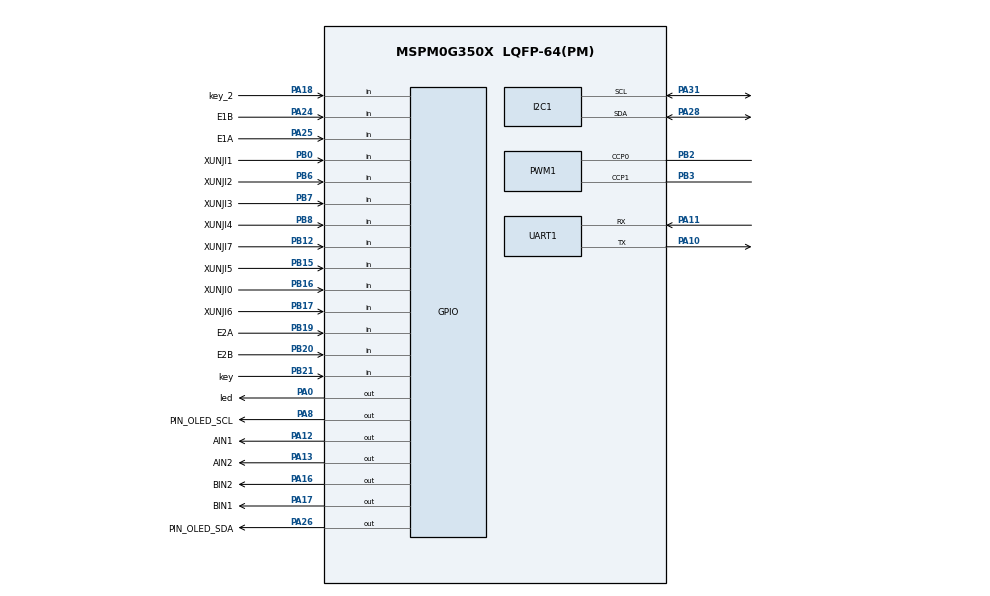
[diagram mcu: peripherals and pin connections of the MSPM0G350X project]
/**
 * @cliArgs --device "MSPM0G350X" --part "Default" --package "LQFP-64(PM)" --product "mspm0_sdk@2.10.00.04"
 * @versions {"tool":"1.27.0+4565"}
 */

/**
 * Import the modules used in this configuration.
 */
const ADC12   = scripting.addModule("/ti/driverlib/ADC12", {}, false);
const ADC121  = ADC12.addInstance();
const GPIO    = scripting.addModule("/ti/driverlib/GPIO", {}, false);
const GPIO1   = GPIO.addInstance();
const GPIO2   = GPIO.addInstance();
const GPIO3   = GPIO.addInstance();
const GPIO4   = GPIO.addInstance();
const GPIO5   = GPIO.addInstance();
const GPIO6   = GPIO.addInstance();
const GPIO7   = GPIO.addInstance();
const GPIO8   = GPIO.addInstance();
const I2C     = scripting.addModule("/ti/driverlib/I2C", {}, false);
const I2C1    = I2C.addInstance();
const PWM     = scripting.addModule("/ti/driverlib/PWM", {}, false);
const PWM1    = PWM.addInstance();
const SYSCTL  = scripting.addModule("/ti/driverlib/SYSCTL");
const SYSTICK = scripting.addModule("/ti/driverlib/SYSTICK");
const TIMER   = scripting.addModule("/ti/driverlib/TIMER", {}, false);
const TIMER1  = TIMER.addInstance();
const UART    = scripting.addModule("/ti/driverlib/UART", {}, false);
const UART1   = UART.addInstance();
const UART2   = UART.addInstance();

/**
 * Write custom configuration values to the imported modules.
 */
const divider7       = system.clockTree["PLL_PDIV"];
divider7.divideValue = 2;

const divider9       = system.clockTree["UDIV"];
divider9.divideValue = 2;

const gate7  = system.clockTree["MFCLKGATE"];
gate7.enable = true;

const multiplier2         = system.clockTree["PLL_QDIV"];
multiplier2.multiplyValue = 5;

const mux8       = system.clockTree["HSCLKMUX"];
mux8.inputSelect = "HSCLKMUX_SYSPLL2X";

ADC121.$name                      = "ADC12_0";
ADC121.resolution                 = "DL_ADC12_SAMP_CONV_RES_10_BIT";
ADC121.peripheral.adcPin0.$assign = "PA15";
ADC121.adcPin0Config.$name        = "ti_driverlib_gpio_GPIOPinGeneric0";

const Board = scripting.addModule("/ti/driverlib/Board", {}, false);

GPIO1.$name                              = "KEY";
GPIO1.associatedPins.create(2);
GPIO1.associatedPins[0].$name            = "key";
GPIO1.associatedPins[0].direction        = "INPUT";
GPIO1.associatedPins[0].internalResistor = "PULL_UP";
GPIO1.associatedPins[0].invert           = "ENABLE";
GPIO1.associatedPins[0].pin.$assign      = "PB21";
GPIO1.associatedPins[1].$name            = "key_2";
GPIO1.associatedPins[1].direction        = "INPUT";
GPIO1.associatedPins[1].invert           = "ENABLE";
GPIO1.associatedPins[1].internalResistor = "PULL_DOWN";
GPIO1.associatedPins[1].pin.$assign      = "PA18";

GPIO2.$name                         = "LED";
GPIO2.associatedPins[0].$name       = "led";
GPIO2.associatedPins[0].pin.$assign = "PA0";

GPIO3.port                          = "PORTA";
GPIO3.$name                         = "BIN";
GPIO3.associatedPins.create(2);
GPIO3.associatedPins[0].$name       = "BIN1";
GPIO3.associatedPins[0].pin.$assign = "PA17";
GPIO3.associatedPins[1].$name       = "BIN2";
GPIO3.associatedPins[1].pin.$assign = "PA16";

GPIO4.$name                         = "AIN";
GPIO4.port                          = "PORTA";
GPIO4.associatedPins.create(2);
GPIO4.associatedPins[0].$name       = "AIN1";
GPIO4.associatedPins[0].pin.$assign = "PA12";
GPIO4.associatedPins[1].$name       = "AIN2";
GPIO4.associatedPins[1].pin.$assign = "PA13";

GPIO5.$name                               = "ENCODERA";
GPIO5.associatedPins.create(2);
GPIO5.associatedPins[0].$name             = "E1A";
GPIO5.associatedPins[0].direction         = "INPUT";
GPIO5.associatedPins[0].polarity          = "RISE";
GPIO5.associatedPins[0].interruptPriority = "0";
GPIO5.associatedPins[0].interruptEn       = true;
GPIO5.associatedPins[0].internalResistor  = "PULL_UP";
GPIO5.associatedPins[0].pin.$assign       = "PA25";
GPIO5.associatedPins[1].$name             = "E1B";
GPIO5.associatedPins[1].direction         = "INPUT";
GPIO5.associatedPins[1].polarity          = "RISE";
GPIO5.associatedPins[1].interruptPriority = "0";
GPIO5.associatedPins[1].interruptEn       = true;
GPIO5.associatedPins[1].internalResistor  = "PULL_UP";
GPIO5.associatedPins[1].pin.$assign       = "PA24";

GPIO6.$name                               = "ENCODERB";
GPIO6.associatedPins.create(2);
GPIO6.associatedPins[0].$name             = "E2A";
GPIO6.associatedPins[0].direction         = "INPUT";
GPIO6.associatedPins[0].polarity          = "RISE";
GPIO6.associatedPins[0].interruptPriority = "0";
GPIO6.associatedPins[0].interruptEn       = true;
GPIO6.associatedPins[0].internalResistor  = "PULL_UP";
GPIO6.associatedPins[0].pin.$assign       = "PB19";
GPIO6.associatedPins[1].$name             = "E2B";
GPIO6.associatedPins[1].direction         = "INPUT";
GPIO6.associatedPins[1].polarity          = "RISE";
GPIO6.associatedPins[1].interruptPriority = "0";
GPIO6.associatedPins[1].interruptEn       = true;
GPIO6.associatedPins[1].internalResistor  = "PULL_UP";
GPIO6.associatedPins[1].pin.$assign       = "PB20";

GPIO7.$name                         = "XUNJI";
GPIO7.associatedPins.create(8);
GPIO7.associatedPins[0].direction   = "INPUT";
GPIO7.associatedPins[0].$name       = "XUNJI0";
GPIO7.associatedPins[0].pin.$assign = "PB16";
GPIO7.associatedPins[1].$name       = "XUNJI1";
GPIO7.associatedPins[1].direction   = "INPUT";
GPIO7.associatedPins[1].pin.$assign = "PB0";
GPIO7.associatedPins[2].$name       = "XUNJI2";
GPIO7.associatedPins[2].direction   = "INPUT";
GPIO7.associatedPins[2].pin.$assign = "PB6";
GPIO7.associatedPins[3].$name       = "XUNJI3";
GPIO7.associatedPins[3].direction   = "INPUT";
GPIO7.associatedPins[3].pin.$assign = "PB7";
GPIO7.associatedPins[4].$name       = "XUNJI4";
GPIO7.associatedPins[4].direction   = "INPUT";
GPIO7.associatedPins[4].pin.$assign = "PB8";
GPIO7.associatedPins[5].$name       = "XUNJI5";
GPIO7.associatedPins[5].direction   = "INPUT";
GPIO7.associatedPins[5].pin.$assign = "PB15";
GPIO7.associatedPins[6].$name       = "XUNJI6";
GPIO7.associatedPins[6].direction   = "INPUT";
GPIO7.associatedPins[6].pin.$assign = "PB17";
GPIO7.associatedPins[7].$name       = "XUNJI7";
GPIO7.associatedPins[7].direction   = "INPUT";
GPIO7.associatedPins[7].pin.$assign = "PB12";

GPIO8.$name                         = "GPIO_OLED";
GPIO8.associatedPins.create(2);
GPIO8.associatedPins[0].$name       = "PIN_OLED_SCL";
GPIO8.associatedPins[0].pin.$assign = "PA8";
GPIO8.associatedPins[1].$name       = "PIN_OLED_SDA";
GPIO8.associatedPins[1].pin.$assign = "PA26";

I2C1.$name                             = "I2C_GYRO";
I2C1.basicEnableController             = true;
I2C1.basicControllerStandardBusSpeed   = "Fast";
I2C1.peripheral.$assign                = "I2C0";
I2C1.peripheral.sdaPin.$assign         = "PA28";
I2C1.peripheral.sclPin.$assign         = "PA31";
I2C1.sdaPinConfig.$name                = "ti_driverlib_gpio_GPIOPinGeneric1";
I2C1.sdaPinConfig.hideOutputInversion  = scripting.forceWrite(false);
I2C1.sdaPinConfig.onlyInternalResistor = scripting.forceWrite(false);
I2C1.sdaPinConfig.passedPeripheralType = scripting.forceWrite("Digital");
I2C1.sdaPinConfig.enableConfig         = true;
I2C1.sdaPinConfig.internalResistor     = "PULL_UP";
I2C1.sclPinConfig.hideOutputInversion  = scripting.forceWrite(false);
I2C1.sclPinConfig.onlyInternalResistor = scripting.forceWrite(false);
I2C1.sclPinConfig.passedPeripheralType = scripting.forceWrite("Digital");
I2C1.sclPinConfig.$name                = "ti_driverlib_gpio_GPIOPinGeneric6";
I2C1.sclPinConfig.enableConfig         = true;
I2C1.sclPinConfig.internalResistor     = "PULL_UP";

PWM1.$name                      = "PWM_0";
PWM1.timerStartTimer            = true;
PWM1.pwmMode                    = "EDGE_ALIGN_UP";
PWM1.timerCount                 = 100;
PWM1.clockDivider               = 4;
PWM1.peripheral.$assign         = "TIMA1";
PWM1.peripheral.ccp0Pin.$assign = "PB2";
PWM1.peripheral.ccp1Pin.$assign = "PB3";
PWM1.PWM_CHANNEL_0.$name        = "ti_driverlib_pwm_PWMTimerCC0";
PWM1.PWM_CHANNEL_1.$name        = "ti_driverlib_pwm_PWMTimerCC1";
PWM1.ccp0PinConfig.$name        = "ti_driverlib_gpio_GPIOPinGeneric4";
PWM1.ccp1PinConfig.$name        = "ti_driverlib_gpio_GPIOPinGeneric5";

SYSCTL.forceDefaultClkConfig = true;

SYSTICK.periodEnable  = true;
SYSTICK.systickEnable = true;
SYSTICK.period        = 16777216;

TIMER1.$name              = "TIMER_0";
TIMER1.timerClkPrescale   = 32;
TIMER1.timerMode          = "PERIODIC";
TIMER1.timerStartTimer    = true;
TIMER1.interrupts         = ["ZERO"];
TIMER1.timerPeriod        = "20ms";
TIMER1.peripheral.$assign = "TIMG0";

UART1.$name                    = "UART_0";
UART1.targetBaudRate           = 115200;
UART1.enableFIFO               = true;
UART1.rxFifoThreshold          = "DL_UART_RX_FIFO_LEVEL_ONE_ENTRY";
UART1.enableDMARX              = false;
UART1.enableDMATX              = false;
UART1.enabledInterrupts        = ["RX","RX_TIMEOUT_ERROR"];
UART1.peripheral.rxPin.$assign = "PA11";
UART1.peripheral.txPin.$assign = "PA10";
UART1.txPinConfig.$name        = "ti_driverlib_gpio_GPIOPinGeneric2";
UART1.rxPinConfig.$name        = "ti_driverlib_gpio_GPIOPinGeneric3";

UART2.$name             = "UART_1";
UART2.targetBaudRate    = 115200;
UART2.enableFIFO        = true;
UART2.rxFifoThreshold   = "DL_UART_RX_FIFO_LEVEL_ONE_ENTRY";
UART2.enabledInterrupts = ["RX","RX_TIMEOUT_ERROR"];
UART2.txPinConfig.$name = "ti_driverlib_gpio_GPIOPinGeneric7";
UART2.rxPinConfig.$name = "ti_driverlib_gpio_GPIOPinGeneric8";

/**
 * Pinmux solution for unlocked pins/peripherals. This ensures that minor changes to the automatic solver in a future
 * version of the tool will not impact the pinmux you originally saw.  These lines can be completely deleted in order to
 * re-solve from scratch.
 */
ADC121.peripheral.$suggestSolution         = "ADC1";
Board.peripheral.$suggestSolution          = "DEBUGSS";
Board.peripheral.swclkPin.$suggestSolution = "PA20";
Board.peripheral.swdioPin.$suggestSolution = "PA19";
SYSCTL.peripheral.$suggestSolution         = "SYSCTL";
UART1.peripheral.$suggestSolution          = "UART0";
UART2.peripheral.$suggestSolution          = "UART1";
UART2.peripheral.rxPin.$suggestSolution    = "PA9";
UART2.peripheral.txPin.$suggestSolution    = "PB4";
